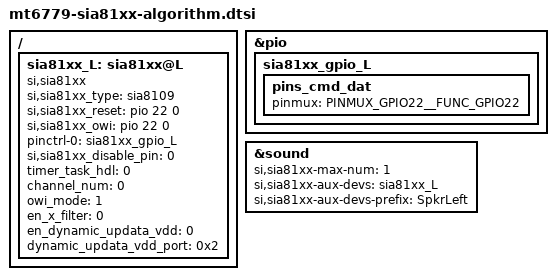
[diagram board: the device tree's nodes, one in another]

/* Copyright (c) 2018, The Linux Foundation. All rights reserved.
 *
 * This program is free software; you can redistribute it and/or modify
 * it under the terms of the GNU General Public License version 2 and
 * only version 2 as published by the Free Software Foundation.
 *
 * This program is distributed in the hope that it will be useful,
 * but WITHOUT ANY WARRANTY; without even the implied warranty of
 * MERCHANTABILITY or FITNESS FOR A PARTICULAR PURPOSE.  See the
 * GNU General Public License for more details.
 */

&pio {
	//#ifdef OPLUS_ARCH_EXTENDS
	sia81xx_gpio_L: sia81xx_gpio_L {
		pins_cmd_dat {
			pinmux = <PINMUX_GPIO22__FUNC_GPIO22>;
		};
	};
	//endif
};

/ {
//#ifdef OPLUS_ARCH_EXTENDS
	sia81xx_L: sia81xx@L {
		compatible = "si,sia81xx";
		si,sia81xx_type = "sia8109";
		si,sia81xx_reset = <&pio 22 0>;
                si,sia81xx_owi = <&pio 22 0>;
		pinctrl-names = "sia81xx_gpio";
		pinctrl-0 = <&sia81xx_gpio_L>;
		si,sia81xx_disable_pin = <0>;
		/* the same value share a same task
		 * valid value range : 0 ~ 7 */
		timer_task_hdl = <0>;

		channel_num = <0>;
		owi_mode = <1>;
		en_x_filter = <0>;
		en_dynamic_updata_vdd = <0>;
		dynamic_updata_vdd_port = <0x2>;
        };
//endif
};

&sound {
//#ifdef OPLUS_ARCH_EXTENDS
		si,sia81xx-max-num = <1>;
		si,sia81xx-aux-devs = <&sia81xx_L>;
		si,sia81xx-aux-devs-prefix = "SpkrLeft";
//#endif
};


